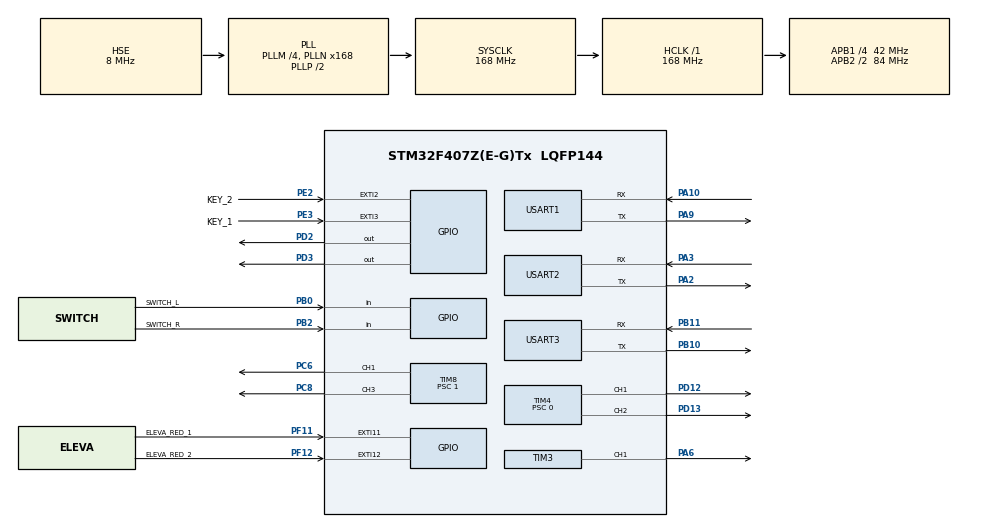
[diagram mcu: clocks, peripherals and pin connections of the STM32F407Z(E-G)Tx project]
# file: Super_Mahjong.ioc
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Dma.Request0=USART2_RX
Dma.Request1=USART2_TX
Dma.Request2=TIM3_CH1/TRIG
Dma.Request3=USART1_RX
Dma.Request4=USART1_TX
Dma.Request5=USART3_RX
Dma.Request6=USART3_TX
Dma.TIM3_CH1/TRIG.2.Direction=DMA_MEMORY_TO_PERIPH
Dma.TIM3_CH1/TRIG.2.FIFOMode=DMA_FIFOMODE_DISABLE
Dma.TIM3_CH1/TRIG.2.Instance=DMA1_Stream4
Dma.TIM3_CH1/TRIG.2.MemDataAlignment=DMA_MDATAALIGN_HALFWORD
Dma.TIM3_CH1/TRIG.2.MemInc=DMA_MINC_ENABLE
Dma.TIM3_CH1/TRIG.2.Mode=DMA_NORMAL
Dma.TIM3_CH1/TRIG.2.PeriphDataAlignment=DMA_PDATAALIGN_HALFWORD
Dma.TIM3_CH1/TRIG.2.PeriphInc=DMA_PINC_DISABLE
Dma.TIM3_CH1/TRIG.2.Priority=DMA_PRIORITY_HIGH
Dma.USART1_RX.3.Direction=DMA_PERIPH_TO_MEMORY
Dma.USART1_RX.3.FIFOMode=DMA_FIFOMODE_DISABLE
Dma.USART1_RX.3.Instance=DMA2_Stream2
Dma.USART1_RX.3.MemDataAlignment=DMA_MDATAALIGN_BYTE
Dma.USART1_RX.3.MemInc=DMA_MINC_ENABLE
Dma.USART1_RX.3.Mode=DMA_NORMAL
Dma.USART1_RX.3.PeriphDataAlignment=DMA_PDATAALIGN_BYTE
Dma.USART1_RX.3.PeriphInc=DMA_PINC_DISABLE
Dma.USART1_RX.3.Priority=DMA_PRIORITY_LOW
Dma.USART1_TX.4.Direction=DMA_MEMORY_TO_PERIPH
Dma.USART1_TX.4.FIFOMode=DMA_FIFOMODE_DISABLE
Dma.USART1_TX.4.Instance=DMA2_Stream7
Dma.USART1_TX.4.MemDataAlignment=DMA_MDATAALIGN_BYTE
Dma.USART1_TX.4.MemInc=DMA_MINC_ENABLE
Dma.USART1_TX.4.Mode=DMA_NORMAL
Dma.USART1_TX.4.PeriphDataAlignment=DMA_PDATAALIGN_BYTE
Dma.USART1_TX.4.PeriphInc=DMA_PINC_DISABLE
Dma.USART1_TX.4.Priority=DMA_PRIORITY_LOW
Dma.USART2_RX.0.Direction=DMA_PERIPH_TO_MEMORY
Dma.USART2_RX.0.FIFOMode=DMA_FIFOMODE_DISABLE
Dma.USART2_RX.0.Instance=DMA1_Stream5
Dma.USART2_RX.0.MemDataAlignment=DMA_MDATAALIGN_BYTE
Dma.USART2_RX.0.MemInc=DMA_MINC_ENABLE
Dma.USART2_RX.0.Mode=DMA_NORMAL
Dma.USART2_RX.0.PeriphDataAlignment=DMA_PDATAALIGN_BYTE
Dma.USART2_RX.0.PeriphInc=DMA_PINC_DISABLE
Dma.USART2_RX.0.Priority=DMA_PRIORITY_LOW
Dma.USART2_TX.1.Direction=DMA_MEMORY_TO_PERIPH
Dma.USART2_TX.1.FIFOMode=DMA_FIFOMODE_DISABLE
Dma.USART2_TX.1.Instance=DMA1_Stream6
Dma.USART2_TX.1.MemDataAlignment=DMA_MDATAALIGN_BYTE
Dma.USART2_TX.1.MemInc=DMA_MINC_ENABLE
Dma.USART2_TX.1.Mode=DMA_NORMAL
Dma.USART2_TX.1.PeriphDataAlignment=DMA_PDATAALIGN_BYTE
Dma.USART2_TX.1.PeriphInc=DMA_PINC_DISABLE
Dma.USART2_TX.1.Priority=DMA_PRIORITY_LOW
Dma.USART3_RX.5.Direction=DMA_PERIPH_TO_MEMORY
Dma.USART3_RX.5.FIFOMode=DMA_FIFOMODE_DISABLE
Dma.USART3_RX.5.Instance=DMA1_Stream1
Dma.USART3_RX.5.MemDataAlignment=DMA_MDATAALIGN_BYTE
Dma.USART3_RX.5.MemInc=DMA_MINC_ENABLE
Dma.USART3_RX.5.Mode=DMA_NORMAL
Dma.USART3_RX.5.PeriphDataAlignment=DMA_PDATAALIGN_BYTE
Dma.USART3_RX.5.PeriphInc=DMA_PINC_DISABLE
Dma.USART3_RX.5.Priority=DMA_PRIORITY_LOW
Dma.USART3_TX.6.Direction=DMA_MEMORY_TO_PERIPH
Dma.USART3_TX.6.FIFOMode=DMA_FIFOMODE_DISABLE
Dma.USART3_TX.6.Instance=DMA1_Stream3
Dma.USART3_TX.6.MemDataAlignment=DMA_MDATAALIGN_BYTE
Dma.USART3_TX.6.MemInc=DMA_MINC_ENABLE
Dma.USART3_TX.6.Mode=DMA_NORMAL
Dma.USART3_TX.6.PeriphDataAlignment=DMA_PDATAALIGN_BYTE
Dma.USART3_TX.6.PeriphInc=DMA_PINC_DISABLE
Dma.USART3_TX.6.Priority=DMA_PRIORITY_LOW
FREERTOS.Tasks01=defaultTask,0,128,StartDefaultTask,Default,NULL,Dynamic,NULL,NULL
Mcu.Family=STM32F4
Mcu.Name=STM32F407Z(E-G)Tx
Mcu.Package=LQFP144
NVIC.DMA1_Stream1_IRQn=true\:5\:0\:false\:false\:true\:true\:false\:true\:true
NVIC.DMA1_Stream3_IRQn=true\:5\:0\:false\:false\:true\:true\:false\:true\:true
NVIC.DMA1_Stream4_IRQn=true\:5\:0\:false\:false\:true\:true\:false\:true\:true
NVIC.DMA1_Stream5_IRQn=true\:5\:0\:false\:false\:true\:true\:false\:true\:true
NVIC.DMA1_Stream6_IRQn=true\:5\:0\:false\:false\:true\:true\:false\:true\:true
NVIC.DMA2_Stream2_IRQn=true\:5\:0\:false\:false\:true\:true\:false\:true\:true
NVIC.DMA2_Stream7_IRQn=true\:5\:0\:false\:false\:true\:true\:false\:true\:true
NVIC.EXTI15_10_IRQn=true\:5\:0\:false\:false\:true\:true\:true\:true\:true
NVIC.EXTI2_IRQn=true\:5\:0\:false\:false\:true\:true\:true\:true\:true
NVIC.EXTI3_IRQn=true\:5\:0\:false\:false\:true\:true\:true\:true\:true
NVIC.PriorityGroup=NVIC_PRIORITYGROUP_4
NVIC.TIM2_IRQn=true\:15\:0\:false\:false\:true\:false\:false\:true\:true
NVIC.TIM3_IRQn=true\:5\:0\:false\:false\:true\:true\:true\:true\:true
NVIC.TIM4_IRQn=true\:5\:0\:false\:false\:true\:true\:true\:true\:true
NVIC.TIM8_BRK_TIM12_IRQn=true\:5\:0\:false\:false\:true\:true\:true\:true\:true
NVIC.TimeBase=TIM2_IRQn
NVIC.TimeBaseIP=TIM2
NVIC.USART1_IRQn=true\:5\:0\:false\:false\:true\:true\:true\:true\:true
NVIC.USART2_IRQn=true\:5\:0\:false\:false\:true\:true\:true\:true\:true
NVIC.USART3_IRQn=true\:5\:0\:false\:false\:true\:true\:true\:true\:true
PA10.Mode=Asynchronous
PA10.Signal=USART1_RX
PA13.Mode=Serial_Wire
PA13.Signal=SYS_JTMS-SWDIO
PA14.Mode=Serial_Wire
PA14.Signal=SYS_JTCK-SWCLK
PA2.Mode=Asynchronous
PA2.Signal=USART2_TX
PA3.Mode=Asynchronous
PA3.Signal=USART2_RX
PA6.Signal=S_TIM3_CH1
PA9.Mode=Asynchronous
PA9.Signal=USART1_TX
PB0.GPIO_Label=SWITCH_L
PB0.Signal=GPIO_Input
PB10.Mode=Asynchronous
PB10.Signal=USART3_TX
PB11.Mode=Asynchronous
PB11.Signal=USART3_RX
PB2.GPIO_Label=SWITCH_R
PB2.Signal=GPIO_Input
PC6.Signal=S_TIM8_CH1
PC8.Signal=S_TIM8_CH3
PD12.Signal=S_TIM4_CH1
PD13.Signal=S_TIM4_CH2
PD2.Signal=GPIO_Output
PD3.Signal=GPIO_Output
PE2.GPIO_Label=KEY_2
PE2.GPIO_ModeDefaultEXTI=GPIO_MODE_IT_FALLING
PE2.GPIO_PuPd=GPIO_PULLUP
PE2.Signal=GPXTI2
PE3.GPIO_Label=KEY_1
PE3.GPIO_ModeDefaultEXTI=GPIO_MODE_IT_FALLING
PE3.GPIO_PuPd=GPIO_PULLUP
PE3.Signal=GPXTI3
PF11.GPIO_Label=ELEVA_RED_1
PF11.GPIO_ModeDefaultEXTI=GPIO_MODE_IT_RISING
PF11.GPIO_PuPd=GPIO_PULLDOWN
PF11.Signal=GPXTI11
PF12.GPIO_Label=ELEVA_RED_2
PF12.GPIO_ModeDefaultEXTI=GPIO_MODE_IT_RISING
PF12.GPIO_PuPd=GPIO_PULLDOWN
PF12.Signal=GPXTI12
PH0-OSC_IN.Mode=HSE-External-Oscillator
PH0-OSC_IN.Signal=RCC_OSC_IN
PH1-OSC_OUT.Mode=HSE-External-Oscillator
PH1-OSC_OUT.Signal=RCC_OSC_OUT
ProjectManager.HeapSize=0x200
ProjectManager.StackSize=0x400
ProjectManager.TargetToolchain=Makefile
RCC.48MHZClocksFreq_Value=84000000
RCC.AHBFreq_Value=168000000
RCC.APB1CLKDivider=RCC_HCLK_DIV4
RCC.APB1Freq_Value=42000000
RCC.APB1TimFreq_Value=84000000
RCC.APB2CLKDivider=RCC_HCLK_DIV2
RCC.APB2Freq_Value=84000000
RCC.APB2TimFreq_Value=168000000
RCC.CortexFreq_Value=168000000
RCC.HCLKFreq_Value=168000000
RCC.HSE_VALUE=8000000
RCC.HSI_VALUE=16000000
RCC.LSE_VALUE=32768
RCC.PLLM=4
RCC.PLLN=168
RCC.PLLSourceVirtual=RCC_PLLSOURCE_HSE
RCC.SYSCLKFreq_VALUE=168000000
RCC.SYSCLKSource=RCC_SYSCLKSOURCE_PLLCLK
RCC.VCOOutputFreq_Value=336000000
SH.S_TIM3_CH1.0=TIM3_CH1,PWM Generation1 CH1
SH.S_TIM4_CH1.0=TIM4_CH1,PWM Generation1 CH1
SH.S_TIM4_CH2.0=TIM4_CH2,PWM Generation2 CH2
SH.S_TIM8_CH1.0=TIM8_CH1,PWM Generation1 CH1
SH.S_TIM8_CH3.0=TIM8_CH3,PWM Generation3 CH3
STMicroelectronics.X-CUBE-ALGOBUILD.1.4.0.LibraryCcDSPOoLibraryJjDSPOoLibrary=true
TIM3.Channel-PWM\ Generation1\ CH1=TIM_CHANNEL_1
TIM3.Period=105-1
TIM3.Prescaler=0
TIM4.Channel-PWM\ Generation1\ CH1=TIM_CHANNEL_1
TIM4.Channel-PWM\ Generation2\ CH2=TIM_CHANNEL_2
TIM4.Period=8399
TIM4.Prescaler=0
TIM8.Channel-PWM\ Generation1\ CH1=TIM_CHANNEL_1
TIM8.Channel-PWM\ Generation3\ CH3=TIM_CHANNEL_3
TIM8.Period=8399
TIM8.Prescaler=1
USART1.VirtualMode=VM_ASYNC
USART2.VirtualMode=VM_ASYNC
USART3.VirtualMode=VM_ASYNC
VP_FREERTOS_VS_CMSIS_V1.Mode=CMSIS_V1
VP_STMicroelectronics.X-CUBE-ALGOBUILD_VS_DSPOoLibraryJjLibrary_1.4.0_1.4.0.Mode=DSPOoLibraryJjLibrary
VP_SYS_VS_tim2.Mode=TIM2
VP_TIM3_VS_ClockSourceINT.Mode=Internal
board=custom

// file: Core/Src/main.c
/* USER CODE BEGIN Header */
/**
 ******************************************************************************
 * @file           : main.c
 * @brief          : Main program body
 ******************************************************************************
 * @attention
 *
 * Copyright (c) 2025 STMicroelectronics.
 * All rights reserved.
 *
 * This software is licensed under terms that can be found in the LICENSE file
 * in the root directory of this software component.
 * If no LICENSE file comes with this software, it is provided AS-IS.
 *
 ******************************************************************************
 */
/* USER CODE END Header */
#include "main.h"
#include "cmsis_os.h"
#include "dma.h"
#include "tim.h"
#include "usart.h"
#include "gpio.h"

/* USER CODE BEGIN Includes */
#include "robot.h"
/* USER CODE END Includes */

void SystemClock_Config(void);
void MX_FREERTOS_Init(void);

int main(void)
{

  /* MCU Configuration--------------------------------------------------------*/

  /* Reset of all peripherals, Initializes the Flash interface and the Systick. */
  HAL_Init();

  /* Configure the system clock */
  SystemClock_Config();

  /* Initialize all configured peripherals */
  MX_GPIO_Init();
  MX_DMA_Init();
  MX_USART2_UART_Init();
  MX_USART3_UART_Init();
  MX_TIM3_Init();
  MX_USART1_UART_Init();
  MX_TIM4_Init();
  MX_TIM8_Init();
  /* USER CODE BEGIN 2 */
  RobotInit(); // Initialize the robot system
  /* USER CODE END 2 */

  /* Call init function for freertos objects (in cmsis_os2.c) */
  MX_FREERTOS_Init();

  /* Start scheduler */
  osKernelStart();

  /* We should never get here as control is now taken by the scheduler */

  /* Infinite loop */
  while (1)
  {

  }
}

void SystemClock_Config(void)
{
  RCC_OscInitTypeDef RCC_OscInitStruct = {0};
  RCC_ClkInitTypeDef RCC_ClkInitStruct = {0};

  /** Configure the main internal regulator output voltage
  */
  __HAL_RCC_PWR_CLK_ENABLE();
  __HAL_PWR_VOLTAGESCALING_CONFIG(PWR_REGULATOR_VOLTAGE_SCALE1);

  /** Initializes the RCC Oscillators according to the specified parameters
  * in the RCC_OscInitTypeDef structure.
  */
  RCC_OscInitStruct.OscillatorType = RCC_OSCILLATORTYPE_HSE;
  RCC_OscInitStruct.HSEState = RCC_HSE_ON;
  RCC_OscInitStruct.PLL.PLLState = RCC_PLL_ON;
  RCC_OscInitStruct.PLL.PLLSource = RCC_PLLSOURCE_HSE;
  RCC_OscInitStruct.PLL.PLLM = 4;
  RCC_OscInitStruct.PLL.PLLN = 168;
  RCC_OscInitStruct.PLL.PLLP = RCC_PLLP_DIV2;
  RCC_OscInitStruct.PLL.PLLQ = 4;
  if (HAL_RCC_OscConfig(&RCC_OscInitStruct) != HAL_OK)
  {
    Error_Handler();
  }

  /** Initializes the CPU, AHB and APB buses clocks
  */
  RCC_ClkInitStruct.ClockType = RCC_CLOCKTYPE_HCLK|RCC_CLOCKTYPE_SYSCLK
                              |RCC_CLOCKTYPE_PCLK1|RCC_CLOCKTYPE_PCLK2;
  RCC_ClkInitStruct.SYSCLKSource = RCC_SYSCLKSOURCE_PLLCLK;
  RCC_ClkInitStruct.AHBCLKDivider = RCC_SYSCLK_DIV1;
  RCC_ClkInitStruct.APB1CLKDivider = RCC_HCLK_DIV4;
  RCC_ClkInitStruct.APB2CLKDivider = RCC_HCLK_DIV2;

  if (HAL_RCC_ClockConfig(&RCC_ClkInitStruct, FLASH_LATENCY_5) != HAL_OK)
  {
    Error_Handler();
  }
}

void HAL_TIM_PeriodElapsedCallback(TIM_HandleTypeDef *htim)
{
  if (htim->Instance == TIM2)
  {
    HAL_IncTick();
  }
}

void Error_Handler(void)
{
  __disable_irq();
  while (1)
  {
  }
}
